VERSION ""

NS_ :

BS_:

BU_: BMS VCU BCM TESTER

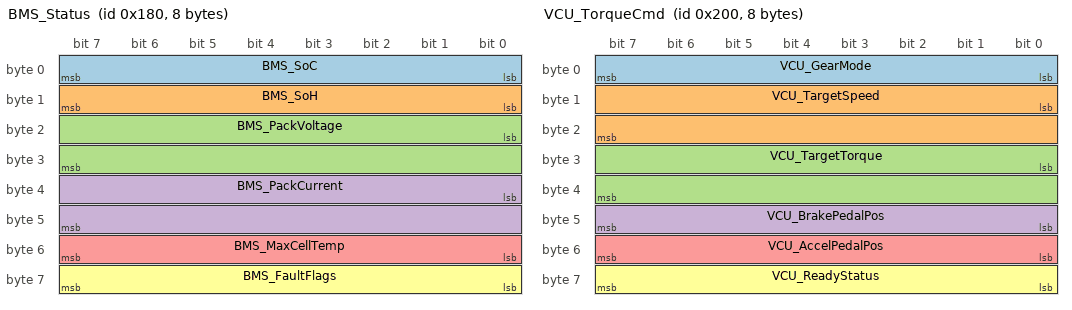
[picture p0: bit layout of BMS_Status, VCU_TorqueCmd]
BO_ 384 BMS_Status: 8 BMS
 SG_ BMS_SoC : 0|8@1+ (1,0) [0|100] "%" Vector__XXX
 SG_ BMS_SoH : 8|8@1+ (1,0) [0|100] "%" Vector__XXX
 SG_ BMS_PackVoltage : 16|16@1+ (0.1,0) [0|1000] "V" Vector__XXX
 SG_ BMS_PackCurrent : 32|16@1- (0.1,0) [-500|500] "A" Vector__XXX
 SG_ BMS_MaxCellTemp : 48|8@1+ (1,-40) [-40|120] "degC" Vector__XXX
 SG_ BMS_FaultFlags : 56|8@1+ (1,0) [0|255] "" Vector__XXX

BO_ 512 VCU_TorqueCmd: 8 VCU
 SG_ VCU_GearMode : 0|8@1+ (1,0) [0|4] "" Vector__XXX
 SG_ VCU_TargetSpeed : 8|16@1+ (1,0) [0|300] "km/h" Vector__XXX
 SG_ VCU_TargetTorque : 24|16@1- (1,0) [-500|500] "Nm" Vector__XXX
 SG_ VCU_BrakePedalPos : 40|8@1+ (0.5,0) [0|100] "%" Vector__XXX
 SG_ VCU_AccelPedalPos : 48|8@1+ (0.5,0) [0|100] "%" Vector__XXX
 SG_ VCU_ReadyStatus : 56|8@1+ (1,0) [0|1] "" Vector__XXX

VAL_ 512 VCU_GearMode 0 "PARK" 1 "REVERSE" 2 "NEUTRAL" 3 "DRIVE" 4 "SPORT" ;
VAL_ 512 VCU_ReadyStatus 0 "NOT_READY" 1 "READY" ;
